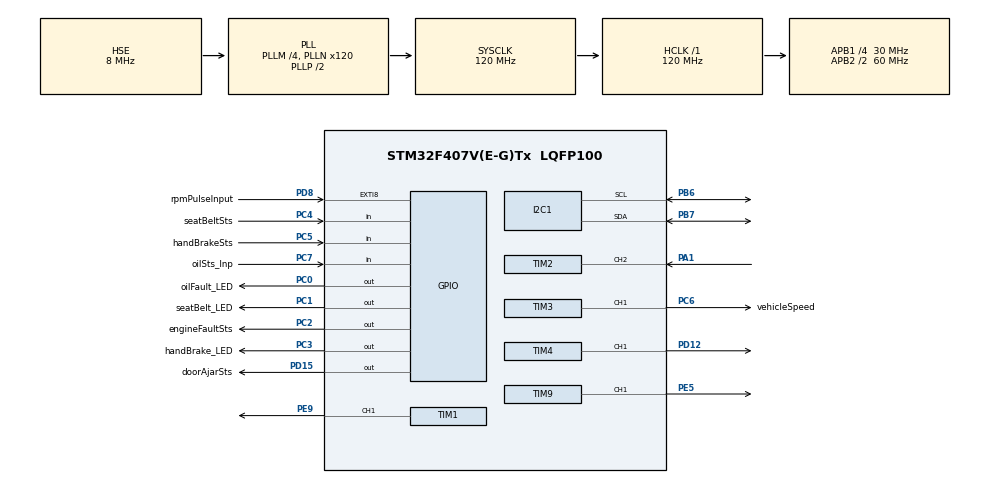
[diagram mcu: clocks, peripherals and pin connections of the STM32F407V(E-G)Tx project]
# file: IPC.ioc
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Mcu.Family=STM32F4
Mcu.Name=STM32F407V(E-G)Tx
Mcu.Package=LQFP100
NVIC.EXTI9_5_IRQn=true\:0\:0\:false\:false\:true\:true\:true
NVIC.PriorityGroup=NVIC_PRIORITYGROUP_0
NVIC.TIM2_IRQn=true\:0\:0\:false\:false\:true\:true\:true
NVIC.TIM6_DAC_IRQn=true\:0\:0\:false\:false\:true\:true\:true
PA1.Signal=S_TIM2_CH2
PA13.Mode=Serial_Wire
PA13.Signal=SYS_JTMS-SWDIO
PA14.Mode=Serial_Wire
PA14.Signal=SYS_JTCK-SWCLK
PB6.Mode=I2C
PB6.Signal=I2C1_SCL
PB7.Mode=I2C
PB7.Signal=I2C1_SDA
PC0.GPIO_Label=oilFault_LED
PC0.Signal=GPIO_Output
PC1.GPIO_Label=seatBelt_LED
PC1.Signal=GPIO_Output
PC14-OSC32_IN.Mode=LSE-External-Oscillator
PC14-OSC32_IN.Signal=RCC_OSC32_IN
PC15-OSC32_OUT.Mode=LSE-External-Oscillator
PC15-OSC32_OUT.Signal=RCC_OSC32_OUT
PC2.GPIO_Label=engineFaultSts
PC2.Signal=GPIO_Output
PC3.GPIO_Label=handBrake_LED
PC3.Signal=GPIO_Output
PC4.GPIO_Label=seatBeltSts
PC4.Signal=GPIO_Input
PC5.GPIO_Label=handBrakeSts
PC5.Signal=GPIO_Input
PC6.GPIO_Label=vehicleSpeed
PC6.Signal=S_TIM3_CH1
PC7.GPIO_Label=oilSts_Inp
PC7.Signal=GPIO_Input
PC8.GPIO_Label=engineRPM_Indicator
PC8.Signal=S_TIM3_CH3
PC9.GPIO_Label=engineTempIndicator
PC9.Signal=S_TIM3_CH4
PD12.Signal=S_TIM4_CH1
PD15.GPIO_Label=doorAjarSts
PD15.Signal=GPIO_Output
PD8.GPIO_Label=rpmPulseInput
PD8.GPIO_ModeDefaultEXTI=GPIO_MODE_IT_RISING
PD8.GPIO_PuPd=GPIO_PULLDOWN
PD8.Signal=GPXTI8
PE5.Signal=S_TIM9_CH1
PE9.Signal=S_TIM1_CH1
PH0-OSC_IN.Mode=HSE-External-Oscillator
PH0-OSC_IN.Signal=RCC_OSC_IN
PH1-OSC_OUT.Mode=HSE-External-Oscillator
PH1-OSC_OUT.Signal=RCC_OSC_OUT
ProjectManager.HeapSize=0x200
ProjectManager.StackSize=0x400
ProjectManager.TargetToolchain=STM32CubeIDE
RCC.48MHZClocksFreq_Value=34285714.28571428
RCC.AHBFreq_Value=120000000
RCC.APB1CLKDivider=RCC_HCLK_DIV4
RCC.APB1Freq_Value=30000000
RCC.APB1TimFreq_Value=60000000
RCC.APB2CLKDivider=RCC_HCLK_DIV2
RCC.APB2Freq_Value=60000000
RCC.APB2TimFreq_Value=120000000
RCC.CortexFreq_Value=120000000
RCC.HCLKFreq_Value=120000000
RCC.HSE_VALUE=8000000
RCC.HSI_VALUE=16000000
RCC.PLLM=4
RCC.PLLN=120
RCC.PLLQ=7
RCC.PLLSourceVirtual=RCC_PLLSOURCE_HSE
RCC.SYSCLKFreq_VALUE=120000000
RCC.SYSCLKSource=RCC_SYSCLKSOURCE_PLLCLK
RCC.VCOOutputFreq_Value=240000000
SH.S_TIM1_CH1.0=TIM1_CH1,PWM Generation1 CH1
SH.S_TIM2_CH2.0=TIM2_CH2,Input_Capture2_from_TI2
SH.S_TIM3_CH1.0=TIM3_CH1,PWM Generation1 CH1
SH.S_TIM3_CH3.0=TIM3_CH3
SH.S_TIM3_CH4.0=TIM3_CH4
SH.S_TIM4_CH1.0=TIM4_CH1,PWM Generation1 CH1
SH.S_TIM9_CH1.0=TIM9_CH1,PWM Generation1 CH1
TIM1.AutoReloadPreload=TIM_AUTORELOAD_PRELOAD_ENABLE
TIM1.Channel-PWM\ Generation1\ CH1=TIM_CHANNEL_1
TIM1.Period=2000
TIM1.Prescaler=599
TIM2.Channel-Input_Capture2_from_TI2=TIM_CHANNEL_2
TIM2.Period=12000
TIM2.Prescaler=99
TIM3.AutoReloadPreload=TIM_AUTORELOAD_PRELOAD_ENABLE
TIM3.Channel-PWM\ Generation1\ CH1=TIM_CHANNEL_1
TIM3.Period=6000
TIM3.Prescaler=599
TIM4.Channel-PWM\ Generation1\ CH1=TIM_CHANNEL_1
TIM6.AutoReloadPreload=TIM_AUTORELOAD_PRELOAD_ENABLE
TIM6.Period=10000
TIM6.Prescaler=5999
TIM6.TIM_MasterOutputTrigger=TIM_TRGO_UPDATE
TIM9.AutoReloadPreload=TIM_AUTORELOAD_PRELOAD_ENABLE
TIM9.Channel-PWM\ Generation1\ CH1=TIM_CHANNEL_1
TIM9.Period=6000
TIM9.Prescaler=599
VP_RTC_VS_RTC_Activate.Mode=RTC_Enabled
VP_TIM1_VS_ClockSourceINT.Mode=Internal
VP_TIM2_VS_ClockSourceINT.Mode=Internal
VP_TIM3_VS_ClockSourceINT.Mode=Internal
VP_TIM4_VS_ClockSourceINT.Mode=Internal
VP_TIM6_VS_ClockSourceINT.Mode=Enable_Timer
VP_TIM9_VS_ClockSourceINT.Mode=Internal
board=STM32F407G-DISC1

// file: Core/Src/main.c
/* USER CODE BEGIN Header */
/**
  ******************************************************************************
  * @file           : main.c
  * @brief          : Main program body
  ******************************************************************************
  * @attention
  *
  * <h2><center>&copy; Copyright (c) 2020 STMicroelectronics.
  * All rights reserved.</center></h2>
  *
  * This software component is licensed by ST under Ultimate Liberty license
  * SLA0044, the "License"; You may not use this file except in compliance with
  * the License. You may obtain a copy of the License at:
  *                             www.st.com/SLA0044
  *
  ******************************************************************************
  */
/* USER CODE END Header */

#include "main.h"

/* USER CODE BEGIN Includes */
#include "engineData.h"
/* USER CODE END Includes */

I2C_HandleTypeDef hi2c1;

RTC_HandleTypeDef hrtc;

TIM_HandleTypeDef htim1;
TIM_HandleTypeDef htim2;
TIM_HandleTypeDef htim3;
TIM_HandleTypeDef htim4;
TIM_HandleTypeDef htim6;
TIM_HandleTypeDef htim9;

void SystemClock_Config(void);
static void MX_GPIO_Init(void);
static void MX_TIM2_Init(void);
static void MX_TIM4_Init(void);
static void MX_I2C1_Init(void);
static void MX_RTC_Init(void);
static void MX_TIM6_Init(void);
static void MX_TIM1_Init(void);
static void MX_TIM3_Init(void);
static void MX_TIM9_Init(void);

int main(void)
{

  /* MCU Configuration--------------------------------------------------------*/

  /* Reset of all peripherals, Initializes the Flash interface and the Systick. */
  HAL_Init();

  /* Configure the system clock */
  SystemClock_Config();

  /* Initialize all configured peripherals */
  MX_GPIO_Init();
  MX_TIM2_Init();
  MX_TIM4_Init();
  MX_I2C1_Init();
  MX_RTC_Init();
  MX_TIM6_Init();
  MX_TIM1_Init();
  MX_TIM3_Init();
  MX_TIM9_Init();
  /* USER CODE BEGIN 2 */

power_on();

	// UART_TX("RAM FAILURE");

  /* USER CODE END 2 */

  /* Infinite loop */
  while (1)
  {

  }
}

void SystemClock_Config(void)
{
  RCC_OscInitTypeDef RCC_OscInitStruct = {0};
  RCC_ClkInitTypeDef RCC_ClkInitStruct = {0};
  RCC_PeriphCLKInitTypeDef PeriphClkInitStruct = {0};

  /** Configure the main internal regulator output voltage
  */
  __HAL_RCC_PWR_CLK_ENABLE();
  __HAL_PWR_VOLTAGESCALING_CONFIG(PWR_REGULATOR_VOLTAGE_SCALE1);
  /** Initializes the CPU, AHB and APB busses clocks
  */
  RCC_OscInitStruct.OscillatorType = RCC_OSCILLATORTYPE_LSI|RCC_OSCILLATORTYPE_HSE;
  RCC_OscInitStruct.HSEState = RCC_HSE_ON;
  RCC_OscInitStruct.LSIState = RCC_LSI_ON;
  RCC_OscInitStruct.PLL.PLLState = RCC_PLL_ON;
  RCC_OscInitStruct.PLL.PLLSource = RCC_PLLSOURCE_HSE;
  RCC_OscInitStruct.PLL.PLLM = 4;
  RCC_OscInitStruct.PLL.PLLN = 120;
  RCC_OscInitStruct.PLL.PLLP = RCC_PLLP_DIV2;
  RCC_OscInitStruct.PLL.PLLQ = 7;
  if (HAL_RCC_OscConfig(&RCC_OscInitStruct) != HAL_OK)
  {
    Error_Handler();
  }
  /** Initializes the CPU, AHB and APB busses clocks
  */
  RCC_ClkInitStruct.ClockType = RCC_CLOCKTYPE_HCLK|RCC_CLOCKTYPE_SYSCLK
                              |RCC_CLOCKTYPE_PCLK1|RCC_CLOCKTYPE_PCLK2;
  RCC_ClkInitStruct.SYSCLKSource = RCC_SYSCLKSOURCE_PLLCLK;
  RCC_ClkInitStruct.AHBCLKDivider = RCC_SYSCLK_DIV1;
  RCC_ClkInitStruct.APB1CLKDivider = RCC_HCLK_DIV4;
  RCC_ClkInitStruct.APB2CLKDivider = RCC_HCLK_DIV2;

  if (HAL_RCC_ClockConfig(&RCC_ClkInitStruct, FLASH_LATENCY_3) != HAL_OK)
  {
    Error_Handler();
  }
  PeriphClkInitStruct.PeriphClockSelection = RCC_PERIPHCLK_RTC;
  PeriphClkInitStruct.RTCClockSelection = RCC_RTCCLKSOURCE_LSI;
  if (HAL_RCCEx_PeriphCLKConfig(&PeriphClkInitStruct) != HAL_OK)
  {
    Error_Handler();
  }
}

static void MX_I2C1_Init(void)
{

  hi2c1.Instance = I2C1;
  hi2c1.Init.ClockSpeed = 100000;
  hi2c1.Init.DutyCycle = I2C_DUTYCYCLE_2;
  hi2c1.Init.OwnAddress1 = 0;
  hi2c1.Init.AddressingMode = I2C_ADDRESSINGMODE_7BIT;
  hi2c1.Init.DualAddressMode = I2C_DUALADDRESS_DISABLE;
  hi2c1.Init.OwnAddress2 = 0;
  hi2c1.Init.GeneralCallMode = I2C_GENERALCALL_DISABLE;
  hi2c1.Init.NoStretchMode = I2C_NOSTRETCH_DISABLE;
  if (HAL_I2C_Init(&hi2c1) != HAL_OK)
  {
    Error_Handler();
  }

}

static void MX_RTC_Init(void)
{

  /** Initialize RTC Only
  */
  hrtc.Instance = RTC;
  hrtc.Init.HourFormat = RTC_HOURFORMAT_24;
  hrtc.Init.AsynchPrediv = 127;
  hrtc.Init.SynchPrediv = 255;
  hrtc.Init.OutPut = RTC_OUTPUT_DISABLE;
  hrtc.Init.OutPutPolarity = RTC_OUTPUT_POLARITY_HIGH;
  hrtc.Init.OutPutType = RTC_OUTPUT_TYPE_OPENDRAIN;
  if (HAL_RTC_Init(&hrtc) != HAL_OK)
  {
    Error_Handler();
  }

}

static void MX_TIM1_Init(void)
{

  TIM_ClockConfigTypeDef sClockSourceConfig = {0};
  TIM_MasterConfigTypeDef sMasterConfig = {0};
  TIM_OC_InitTypeDef sConfigOC = {0};
  TIM_BreakDeadTimeConfigTypeDef sBreakDeadTimeConfig = {0};

  htim1.Instance = TIM1;
  htim1.Init.Prescaler = 599;
  htim1.Init.CounterMode = TIM_COUNTERMODE_UP;
  htim1.Init.Period = 2000;
  htim1.Init.ClockDivision = TIM_CLOCKDIVISION_DIV1;
  htim1.Init.RepetitionCounter = 0;
  htim1.Init.AutoReloadPreload = TIM_AUTORELOAD_PRELOAD_ENABLE;
  if (HAL_TIM_Base_Init(&htim1) != HAL_OK)
  {
    Error_Handler();
  }
  sClockSourceConfig.ClockSource = TIM_CLOCKSOURCE_INTERNAL;
  if (HAL_TIM_ConfigClockSource(&htim1, &sClockSourceConfig) != HAL_OK)
  {
    Error_Handler();
  }
  if (HAL_TIM_PWM_Init(&htim1) != HAL_OK)
  {
    Error_Handler();
  }
  sMasterConfig.MasterOutputTrigger = TIM_TRGO_RESET;
  sMasterConfig.MasterSlaveMode = TIM_MASTERSLAVEMODE_DISABLE;
  if (HAL_TIMEx_MasterConfigSynchronization(&htim1, &sMasterConfig) != HAL_OK)
  {
    Error_Handler();
  }
  sConfigOC.OCMode = TIM_OCMODE_PWM1;
  sConfigOC.Pulse = 0;
  sConfigOC.OCPolarity = TIM_OCPOLARITY_HIGH;
  sConfigOC.OCNPolarity = TIM_OCNPOLARITY_HIGH;
  sConfigOC.OCFastMode = TIM_OCFAST_DISABLE;
  sConfigOC.OCIdleState = TIM_OCIDLESTATE_RESET;
  sConfigOC.OCNIdleState = TIM_OCNIDLESTATE_RESET;
  if (HAL_TIM_PWM_ConfigChannel(&htim1, &sConfigOC, TIM_CHANNEL_1) != HAL_OK)
  {
    Error_Handler();
  }
  sBreakDeadTimeConfig.OffStateRunMode = TIM_OSSR_DISABLE;
  sBreakDeadTimeConfig.OffStateIDLEMode = TIM_OSSI_DISABLE;
  sBreakDeadTimeConfig.LockLevel = TIM_LOCKLEVEL_OFF;
  sBreakDeadTimeConfig.DeadTime = 0;
  sBreakDeadTimeConfig.BreakState = TIM_BREAK_DISABLE;
  sBreakDeadTimeConfig.BreakPolarity = TIM_BREAKPOLARITY_HIGH;
  sBreakDeadTimeConfig.AutomaticOutput = TIM_AUTOMATICOUTPUT_DISABLE;
  if (HAL_TIMEx_ConfigBreakDeadTime(&htim1, &sBreakDeadTimeConfig) != HAL_OK)
  {
    Error_Handler();
  }
  HAL_TIM_MspPostInit(&htim1);

}

static void MX_TIM2_Init(void)
{

  TIM_ClockConfigTypeDef sClockSourceConfig = {0};
  TIM_MasterConfigTypeDef sMasterConfig = {0};
  TIM_IC_InitTypeDef sConfigIC = {0};

  htim2.Instance = TIM2;
  htim2.Init.Prescaler = 99;
  htim2.Init.CounterMode = TIM_COUNTERMODE_UP;
  htim2.Init.Period = 12000;
  htim2.Init.ClockDivision = TIM_CLOCKDIVISION_DIV1;
  htim2.Init.AutoReloadPreload = TIM_AUTORELOAD_PRELOAD_DISABLE;
  if (HAL_TIM_Base_Init(&htim2) != HAL_OK)
  {
    Error_Handler();
  }
  sClockSourceConfig.ClockSource = TIM_CLOCKSOURCE_INTERNAL;
  if (HAL_TIM_ConfigClockSource(&htim2, &sClockSourceConfig) != HAL_OK)
  {
    Error_Handler();
  }
  if (HAL_TIM_IC_Init(&htim2) != HAL_OK)
  {
    Error_Handler();
  }
  sMasterConfig.MasterOutputTrigger = TIM_TRGO_RESET;
  sMasterConfig.MasterSlaveMode = TIM_MASTERSLAVEMODE_DISABLE;
  if (HAL_TIMEx_MasterConfigSynchronization(&htim2, &sMasterConfig) != HAL_OK)
  {
    Error_Handler();
  }
  sConfigIC.ICPolarity = TIM_INPUTCHANNELPOLARITY_RISING;
  sConfigIC.ICSelection = TIM_ICSELECTION_DIRECTTI;
  sConfigIC.ICPrescaler = TIM_ICPSC_DIV1;
  sConfigIC.ICFilter = 0;
  if (HAL_TIM_IC_ConfigChannel(&htim2, &sConfigIC, TIM_CHANNEL_2) != HAL_OK)
  {
    Error_Handler();
  }

}

static void MX_TIM3_Init(void)
{

  TIM_ClockConfigTypeDef sClockSourceConfig = {0};
  TIM_MasterConfigTypeDef sMasterConfig = {0};
  TIM_OC_InitTypeDef sConfigOC = {0};

  htim3.Instance = TIM3;
  htim3.Init.Prescaler = 599;
  htim3.Init.CounterMode = TIM_COUNTERMODE_UP;
  htim3.Init.Period = 6000;
  htim3.Init.ClockDivision = TIM_CLOCKDIVISION_DIV1;
  htim3.Init.AutoReloadPreload = TIM_AUTORELOAD_PRELOAD_ENABLE;
  if (HAL_TIM_Base_Init(&htim3) != HAL_OK)
  {
    Error_Handler();
  }
  sClockSourceConfig.ClockSource = TIM_CLOCKSOURCE_INTERNAL;
  if (HAL_TIM_ConfigClockSource(&htim3, &sClockSourceConfig) != HAL_OK)
  {
    Error_Handler();
  }
  if (HAL_TIM_PWM_Init(&htim3) != HAL_OK)
  {
    Error_Handler();
  }
  sMasterConfig.MasterOutputTrigger = TIM_TRGO_RESET;
  sMasterConfig.MasterSlaveMode = TIM_MASTERSLAVEMODE_DISABLE;
  if (HAL_TIMEx_MasterConfigSynchronization(&htim3, &sMasterConfig) != HAL_OK)
  {
    Error_Handler();
  }
  sConfigOC.OCMode = TIM_OCMODE_PWM1;
  sConfigOC.Pulse = 0;
  sConfigOC.OCPolarity = TIM_OCPOLARITY_HIGH;
  sConfigOC.OCFastMode = TIM_OCFAST_DISABLE;
  if (HAL_TIM_PWM_ConfigChannel(&htim3, &sConfigOC, TIM_CHANNEL_1) != HAL_OK)
  {
    Error_Handler();
  }
  HAL_TIM_MspPostInit(&htim3);

}

static void MX_TIM4_Init(void)
{

  TIM_ClockConfigTypeDef sClockSourceConfig = {0};
  TIM_MasterConfigTypeDef sMasterConfig = {0};
  TIM_OC_InitTypeDef sConfigOC = {0};

  htim4.Instance = TIM4;
  htim4.Init.Prescaler = 0;
  htim4.Init.CounterMode = TIM_COUNTERMODE_UP;
  htim4.Init.Period = 0;
  htim4.Init.ClockDivision = TIM_CLOCKDIVISION_DIV1;
  htim4.Init.AutoReloadPreload = TIM_AUTORELOAD_PRELOAD_DISABLE;
  if (HAL_TIM_Base_Init(&htim4) != HAL_OK)
  {
    Error_Handler();
  }
  sClockSourceConfig.ClockSource = TIM_CLOCKSOURCE_INTERNAL;
  if (HAL_TIM_ConfigClockSource(&htim4, &sClockSourceConfig) != HAL_OK)
  {
    Error_Handler();
  }
  if (HAL_TIM_PWM_Init(&htim4) != HAL_OK)
  {
    Error_Handler();
  }
  sMasterConfig.MasterOutputTrigger = TIM_TRGO_RESET;
  sMasterConfig.MasterSlaveMode = TIM_MASTERSLAVEMODE_DISABLE;
  if (HAL_TIMEx_MasterConfigSynchronization(&htim4, &sMasterConfig) != HAL_OK)
  {
    Error_Handler();
  }
  sConfigOC.OCMode = TIM_OCMODE_PWM1;
  sConfigOC.Pulse = 0;
  sConfigOC.OCPolarity = TIM_OCPOLARITY_HIGH;
  sConfigOC.OCFastMode = TIM_OCFAST_DISABLE;
  if (HAL_TIM_PWM_ConfigChannel(&htim4, &sConfigOC, TIM_CHANNEL_1) != HAL_OK)
  {
    Error_Handler();
  }
  HAL_TIM_MspPostInit(&htim4);

}

static void MX_TIM6_Init(void)
{

  TIM_MasterConfigTypeDef sMasterConfig = {0};

  htim6.Instance = TIM6;
  htim6.Init.Prescaler = 5999;
  htim6.Init.CounterMode = TIM_COUNTERMODE_UP;
  htim6.Init.Period = 10000;
  htim6.Init.AutoReloadPreload = TIM_AUTORELOAD_PRELOAD_ENABLE;
  if (HAL_TIM_Base_Init(&htim6) != HAL_OK)
  {
    Error_Handler();
  }
  sMasterConfig.MasterOutputTrigger = TIM_TRGO_UPDATE;
  sMasterConfig.MasterSlaveMode = TIM_MASTERSLAVEMODE_DISABLE;
  if (HAL_TIMEx_MasterConfigSynchronization(&htim6, &sMasterConfig) != HAL_OK)
  {
    Error_Handler();
  }

}

static void MX_TIM9_Init(void)
{

  TIM_ClockConfigTypeDef sClockSourceConfig = {0};
  TIM_OC_InitTypeDef sConfigOC = {0};

  htim9.Instance = TIM9;
  htim9.Init.Prescaler = 599;
  htim9.Init.CounterMode = TIM_COUNTERMODE_UP;
  htim9.Init.Period = 6000;
  htim9.Init.ClockDivision = TIM_CLOCKDIVISION_DIV1;
  htim9.Init.AutoReloadPreload = TIM_AUTORELOAD_PRELOAD_ENABLE;
  if (HAL_TIM_Base_Init(&htim9) != HAL_OK)
  {
    Error_Handler();
  }
  sClockSourceConfig.ClockSource = TIM_CLOCKSOURCE_INTERNAL;
  if (HAL_TIM_ConfigClockSource(&htim9, &sClockSourceConfig) != HAL_OK)
  {
    Error_Handler();
  }
  if (HAL_TIM_PWM_Init(&htim9) != HAL_OK)
  {
    Error_Handler();
  }
  sConfigOC.OCMode = TIM_OCMODE_PWM1;
  sConfigOC.Pulse = 0;
  sConfigOC.OCPolarity = TIM_OCPOLARITY_HIGH;
  sConfigOC.OCFastMode = TIM_OCFAST_DISABLE;
  if (HAL_TIM_PWM_ConfigChannel(&htim9, &sConfigOC, TIM_CHANNEL_1) != HAL_OK)
  {
    Error_Handler();
  }
  HAL_TIM_MspPostInit(&htim9);

}

static void MX_GPIO_Init(void)
{
  GPIO_InitTypeDef GPIO_InitStruct = {0};

  /* GPIO Ports Clock Enable */
  __HAL_RCC_GPIOE_CLK_ENABLE();
  __HAL_RCC_GPIOC_CLK_ENABLE();
  __HAL_RCC_GPIOH_CLK_ENABLE();
  __HAL_RCC_GPIOA_CLK_ENABLE();
  __HAL_RCC_GPIOD_CLK_ENABLE();
  __HAL_RCC_GPIOB_CLK_ENABLE();

  /*Configure GPIO pin Output Level */
  HAL_GPIO_WritePin(GPIOC, oilFault_LED_Pin|seatBelt_LED_Pin|engineFaultSts_Pin|handBrake_LED_Pin, GPIO_PIN_RESET);

  /*Configure GPIO pin Output Level */
  HAL_GPIO_WritePin(doorAjarSts_GPIO_Port, doorAjarSts_Pin, GPIO_PIN_RESET);

  /*Configure GPIO pins : oilFault_LED_Pin seatBelt_LED_Pin engineFaultSts_Pin handBrake_LED_Pin */
  GPIO_InitStruct.Pin = oilFault_LED_Pin|seatBelt_LED_Pin|engineFaultSts_Pin|handBrake_LED_Pin;
  GPIO_InitStruct.Mode = GPIO_MODE_OUTPUT_PP;
  GPIO_InitStruct.Pull = GPIO_NOPULL;
  GPIO_InitStruct.Speed = GPIO_SPEED_FREQ_LOW;
  HAL_GPIO_Init(GPIOC, &GPIO_InitStruct);

  /*Configure GPIO pins : seatBeltSts_Pin handBrakeSts_Pin oilSts_Inp_Pin */
  GPIO_InitStruct.Pin = seatBeltSts_Pin|handBrakeSts_Pin|oilSts_Inp_Pin;
  GPIO_InitStruct.Mode = GPIO_MODE_INPUT;
  GPIO_InitStruct.Pull = GPIO_NOPULL;
  HAL_GPIO_Init(GPIOC, &GPIO_InitStruct);

  /*Configure GPIO pin : rpmPulseInput_Pin */
  GPIO_InitStruct.Pin = rpmPulseInput_Pin;
  GPIO_InitStruct.Mode = GPIO_MODE_IT_RISING;
  GPIO_InitStruct.Pull = GPIO_PULLDOWN;
  HAL_GPIO_Init(rpmPulseInput_GPIO_Port, &GPIO_InitStruct);

  /*Configure GPIO pin : doorAjarSts_Pin */
  GPIO_InitStruct.Pin = doorAjarSts_Pin;
  GPIO_InitStruct.Mode = GPIO_MODE_OUTPUT_PP;
  GPIO_InitStruct.Pull = GPIO_NOPULL;
  GPIO_InitStruct.Speed = GPIO_SPEED_FREQ_LOW;
  HAL_GPIO_Init(doorAjarSts_GPIO_Port, &GPIO_InitStruct);

  /* EXTI interrupt init*/
  HAL_NVIC_SetPriority(EXTI9_5_IRQn, 0, 0);
  HAL_NVIC_EnableIRQ(EXTI9_5_IRQn);

}

/* USER CODE BEGIN 4 */
void power_on(void)
{
	 if(ram_Test_DataBus() && ram_Test_AddressBus() == NULL)
	 {
		  aux_on_condition();
	 }
}
/* USER CODE END 4 */

void Error_Handler(void)
{
}

/************************ (C) COPYRIGHT STMicroelectronics *****END OF FILE****/
